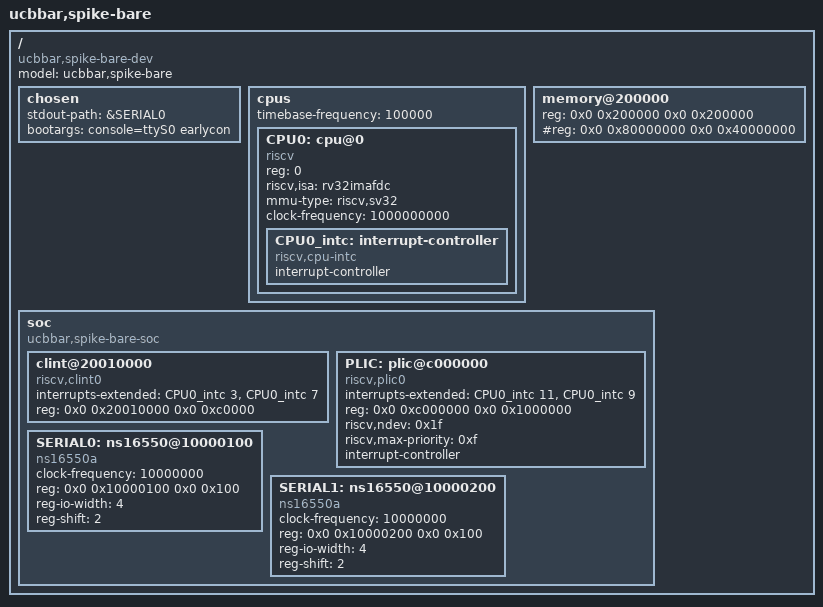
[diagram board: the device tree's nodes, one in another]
/dts-v1/;

/ {
  #address-cells = <2>;
  #size-cells = <2>;
  compatible = "ucbbar,spike-bare-dev";
  model = "ucbbar,spike-bare";
  chosen {
    stdout-path = &SERIAL0;
    bootargs = "console=ttyS0 earlycon";
  };

  cpus {
    #address-cells = <1>;
    #size-cells = <0>;

    timebase-frequency = <100000>;

    CPU0: cpu@0 {
      device_type = "cpu";
      reg = <0>;
      status = "okay";
      compatible = "riscv";
      riscv,isa = "rv32imafdc";
      mmu-type = "riscv,sv32";

      clock-frequency = <1000000000>;

      CPU0_intc: interrupt-controller {
        #interrupt-cells = <1>;
        interrupt-controller;
        compatible = "riscv,cpu-intc";
      };
    };
  };
  memory@200000 {
    device_type = "memory";
    reg = <0x0 0x200000 0x0 0x200000>; #reg = <0x0 0x80000000 0x0 0x40000000>;
  };
  

  
  
  soc {
    #address-cells = <2>;
    #size-cells = <2>;
    compatible = "ucbbar,spike-bare-soc", "simple-bus";
    ranges;
    clint@20010000 {
      compatible = "riscv,clint0";
      interrupts-extended = <&CPU0_intc 3 &CPU0_intc 7>;

      reg = <0x0 0x20010000 0x0 0xc0000>;

    };
    
        PLIC: plic@c000000 {
      compatible = "riscv,plic0";
      #address-cells = <2>;
      interrupts-extended = <&CPU0_intc 11 &CPU0_intc 9 >;
      reg = <0x0 0xc000000 0x0 0x1000000>;
      riscv,ndev = <0x1f>;
      riscv,max-priority = <0xf>;
      #interrupt-cells = <1>;
      interrupt-controller;
    };

    
    
    SERIAL0: ns16550@10000100 {
      compatible = "ns16550a";
      clock-frequency = <10000000>;
      reg = <0x0 0x10000100 0x0 0x100>;
      reg-io-width = <4>;
      reg-shift = <2>;
      
    };
    
        SERIAL1: ns16550@10000200 {
      compatible = "ns16550a";
      clock-frequency = <10000000>;
      reg = <0x0 0x10000200 0x0 0x100>;
      reg-io-width = <4>;
      reg-shift = <2>;
      
    };
    
 };
 };
 
 
 
 
 

